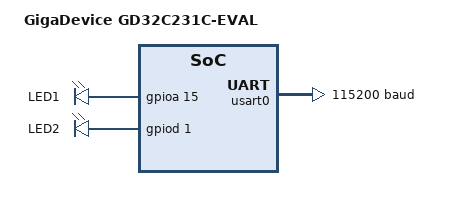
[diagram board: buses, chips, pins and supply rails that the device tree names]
/*
 * Copyright (c) 2026 GigaDevice Semiconductor Inc.
 * SPDX-License-Identifier: Apache-2.0
 */

/dts-v1/;

#include <gd/gd32c2x1/gd32c231c8.dtsi>
#include "gd32c231c_eval-pinctrl.dtsi"

/ {
	model = "GigaDevice GD32C231C-EVAL";
	compatible = "gd,gd32c231c-eval";

	chosen {
		zephyr,flash = &flash0;
		zephyr,sram = &sram0;
		zephyr,console = &usart0;
		zephyr,shell-uart = &usart0;
	};

	leds {
		compatible = "gpio-leds";

		led0: led0 {
			gpios = <&gpioa 15 GPIO_ACTIVE_HIGH>;
			label = "LED1";
		};

		led1: led1 {
			gpios = <&gpiod 1 GPIO_ACTIVE_HIGH>;
			label = "LED2";
		};
	};

	aliases {
		led0 = &led0;
	};
};

&gpioa {
	status = "okay";
};

&gpiod {
	status = "okay";
};

&usart0 {
	status = "okay";
	current-speed = <115200>;
	pinctrl-0 = <&usart0_default>;
	pinctrl-names = "default";
};
